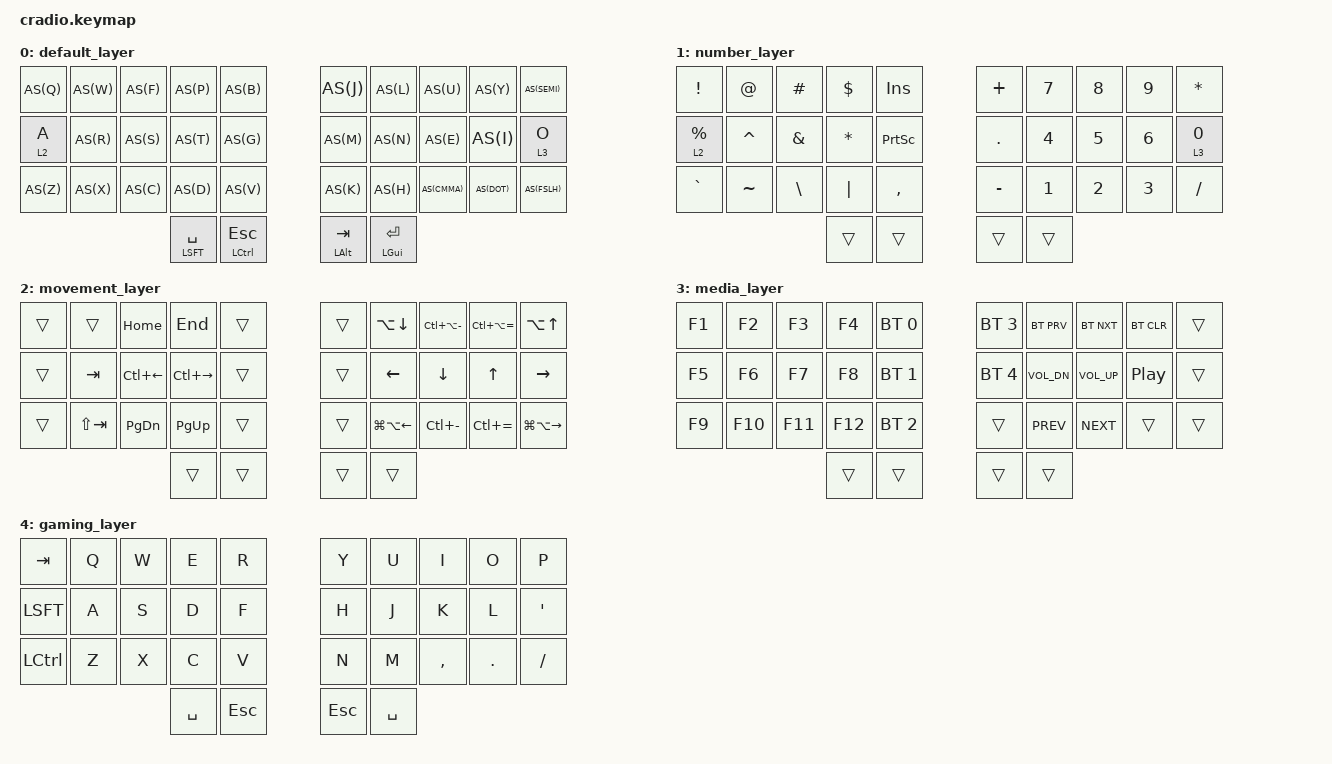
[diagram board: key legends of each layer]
/*
 * Copyright (c) 2020 The ZMK Contributors
 *
 * SPDX-License-Identifier: MIT
 */

#include <behaviors.dtsi>
#include <dt-bindings/zmk/keys.h>
#include <dt-bindings/zmk/bt.h>

#define DEFAULT 0
#define NUMBER 1
#define MOVEMENT 2
#define MEDIA 3
#define GAMING 4


/* Ex command to convert kp to autoshifted key
 *
 * :'<,'>s/\(\&kp \)\([A-Z]+\)/AS(\2)/g
 * */

&mt {
  //  flavor = "tap-preferred";
   // tapping_term_ms = <200>;
};

//give myself a bunch of time to stack modifiers
&sk {
     release-after-ms = <2000>;
};

//allow for adding modifiers to keys on sticky num layer
&sl {
    /delete-property/ quick-release;
};

&caps_word {
continue-list = <UNDERSCORE BSPC MINUS>;
};

#define AS(keycode) &as LS(keycode) keycode
/ {
    macros {
        summon_terminal: zed_em_kay {
            label = "ZM_summon_terminal";
            compatible = "zmk,behavior-macro";
            #binding-cells = <0>;
            bindings
                = <&macro_press &kp LGUI>
                , <&macro_tap &kp RET>
                , <&macro_release &kp LGUI>
                ;
        };

        ZMK_MACRO(my_macro,
            wait-ms = <30>;
            tap-ms = <40>;
            bindings = <&kp Z &kp M &kp K>;
        )
    };
};

/ {
    behaviors {
        as: auto_shift {
            compatible = "zmk,behavior-hold-tap";
            label = "AUTO_SHIFT";
            #binding-cells = <2>;
            tapping_term_ms = <145>;
            quick_tap_ms = <0>;
            flavor = "tap-preferred";
            bindings = <&kp>, <&kp>;
        };

        mo_tog: behavior_mo_tog {
            compatible = "zmk,behavior-hold-tap";
            label = "mo_tog";
            #binding-cells = <2>;
            flavor = "hold-preferred";
            tapping-term-ms = <200>;
            bindings = <&mo>, <&tog>;
        };

        /* sm: behavior_sticky_mo { */
        /*     compatible = "zmk,behavior-hold-tap"; */
        /*     label = "sticky_momentary"; */
        /*     #binding-cells = <2>; */
        /*     flavor = "hold-preferred"; */
        /*     tapping-term-ms = <200>; */
        /*     bindings = <&mo>, <&sl>; */
        /* }; */

        smt: behavior_sticky_mod_tap {
            compatible = "zmk,behavior-hold-tap";
            label = "sticky_mod_tap";
            #binding-cells = <2>;
            flavor = "hold-preferred";
            tapping-term-ms = <200>;
            bindings = <&sk>, <&kp>;
        };

        tph: tap-preferred-hold {
            compatible = "zmk,behavior-hold-tap";
            label = "sticky_mod_tap";
            #binding-cells = <2>;
            flavor = "tap-preferred";
            tapping-term-ms = <200>;
            bindings = <&kp>, <&kp>;
        };

    };

    combos {
        compatible = "zmk,combos";

        combo_del {
            timeout-ms = <50>;
            key-positions = <1 2>;
            bindings = <&kp DEL>;
        };

         combo_backspace {
            timeout-ms = <30>;
            key-positions = <11 12>;
            bindings = <&kp BSPC>;
        };

         combo_backslash {
            timeout-ms = <50>;
            key-positions = <7 8>;
            bindings = <AS(BACKSLASH)>;
        };

         combo_hyphen {
            timeout-ms = <50>;
            key-positions = <13 14>;
            bindings = <AS(MINUS)>;
        };

         combo_underscore {
            timeout-ms = <50>;
            key-positions = <23 24>;
            bindings = <&kp UNDERSCORE>;
        };

         combo_equals {
            timeout-ms = <50>;
            key-positions = <15 16>;
            bindings = <AS(EQUAL)>;
        };

         combo_plus {
            timeout-ms = <50>;
            key-positions = <25 26>;
            bindings = <&kp PLUS>;
        };

          combo_quote_mod {
            timeout-ms = <50>;
            key-positions = <17 18>;
            bindings = <&mt LGUI SQT>;
        };

          combo_double_quote {
            timeout-ms = <50>;
            key-positions = <27 28>;
            bindings = <&kp DOUBLE_QUOTES>;
        };

          combo_numlayer {
            timeout-ms = <50>;
            key-positions = <30 33>;
            bindings = <&sl 1>;
        };

          combo_reset {
            timeout-ms = <50>;
            key-positions = <1 2 7 8>;
            bindings = <&sys_reset>;
        };

          combo_bootloader {
            timeout-ms = <50>;
            key-positions = <3 4 5 6>;
            bindings = <&bootloader>;
        };

          combo_caps_word {
            timeout-ms = <50>;
            key-positions = <31 32>;
            bindings = <&caps_word>;
        };

          combo_num_layer_toggle {
            timeout-ms = <15>;
            key-positions = <10 13>;
            bindings = <&mo_tog 1 1>;
        };


        opening_brace {
            timeout-ms = <15>;
            key-positions = <2 3>;
            bindings = <&kp LBRC>;
        };

        closing_brace {
            timeout-ms = <15>;
            key-positions = <6 7>;
            bindings = <&kp RBRC>;
        };

        opening_par {
            timeout-ms = <15>;
            key-positions = <12 13>;
            bindings = <&kp LPAR>;
        };

        closing_par {
            timeout-ms = <15>;
            key-positions = <16 17>;
            bindings = <&kp RPAR>;
        };

        opening_bracket {
            timeout-ms = <15>;
            key-positions = <22 23>;
            bindings = <&kp LBKT>;
        };

        closing_bracket {
            timeout-ms = <15>;
            key-positions = <26 27>;
            bindings = <&kp RBKT>;
        };

        ralt_left {
            timeout-ms = <30>;
            key-positions = <21 22 23>;
            bindings = <&kp RALT>;
        };

        ralt_right {
            timeout-ms = <30>;
            key-positions = <26 27 28>;
            bindings = <&kp RALT>;
        };

        alt_tab {
            timeout-ms = <50>;
            key-positions = <30 31>;
            bindings = <&kp LA(TAB)>;
        };

        mod_tab {
            timeout-ms = <50>;
            key-positions = <32 33>;
            bindings = <&kp LG(TAB)>;
        };

        gaming_time {
            timeout-ms = <50>;
            key-positions = <2 11 13>;
            bindings = <&tog GAMING>;
        };

        all_thumbs {
            timeout-ms = <50>;
            key-positions = <30 31 32 33>;
            bindings = <&kp LG(LC(RET))>;
        };

        summon_terminal {
            timeout-ms = <50>;
            key-positions = <16 17 18>;
            bindings = <&kp LG(LA(T))>;
        };

        zmk_tester {
            timeout-ms = <50>;
            key-positions = <1 2 3>;
            bindings = <&my_macro>;
        };

};

keymap {
compatible = "zmk,keymap";
/*
                                                 reset
                           ┌─────┬─────────────────┴─────────────────┬─────┐
                           │     │                                   │     │
                           │     │            bootloader             │     │
                           │     │     ┌─────┬─────┴─────┬─────┐     │     │
                  |  q  |  w  |  f  |  p  |  b  |     |  j  |  l  |  u  |  y  |  ;  |
                  |    DEL    |     |     |     |     |     |     |     |     \     |

                  |  a  |  r  |  s  |  t  |  g  |     |  m  |  n  |  e  |  i  |  o  |
                  | lt2 |     |     |     |     |     |     |     |     |     | lt3 |
                  |     |     |     |     |     |     |     |     |     |     '     |
                  |    BSP    |     |     -     |     |     =     |     |    MOD    |

                  |  z  |  x  |  c  |  d  |  v  |     |  k  |  h  |  ,  |  .  |  /  |
                  |     |     |    sl1    |     |     |     |     |     |     |     |
                  |     |     |     |     _     |     |     +     |     |     |     |

                                    | SPC | ESC |     | TAB | ENT |
                                    | SFT | CTL |     | ALT | MOD |
                                       │     └─────┬─────┘     │
                                       │       caps_word       │
                                       │                       │
                                       └───────────┬───────────┘
                                                 ltog1
*/

                default_layer {
        bindings = <
        AS(Q) AS(W) AS(F) AS(P) AS(B)                       AS(J) AS(L)  AS(U)    AS(Y)   AS(SEMI)
        &lt 2 A AS(R) AS(S) AS(T) AS(G)                                 AS(M) AS(N) AS(E) AS(I) &lt 3 O
        AS(Z) AS(X) AS(C) AS(D) AS(V)                      AS(K) AS(H)  AS(CMMA) AS(DOT)  AS(FSLH)
                        &tph LSFT SPC &mt LCTL ESC                   &mt LALT TAB &mt LGUI RET
        >;
        };

/*
                this has changed! no longer a reference
                |  !  |  @  |  {  |  }  |  &  |     | INS |  7  |  8  |  9  |  *  |
                |    DEL    |     |     |     |     |     |     |     |     \     |

                |  #  |  $  |  (  |  )  |  *  |     |  .  |  4  |  5  |  6  |  0  |
                | lt2 |     |     |     |     |     |     |     |     |     | lt3 |
                |    BSP    |     |     -     |     |     =     |     |    MOD    |

                |  %  |  ^  |  [  |  ]  |  `  |     |SYSRQ|  1  |  2  |  3  |  /  |
                |     |     |     |     _     |     |     +     |     |     |     |

                                  | ( ) | ( ) |     | ( ) | ( ) |
*/

                number_layer {
        bindings = <
        &kp EXCL &kp AT &kp HASH &kp DLLR &kp INS                          &kp PLUS &kp N7  &kp N8    &kp N9   &kp ASTRK
        &lt 2 PRCNT &kp CARET &kp AMPS &kp ASTRK &kp PSCRN                   &kp DOT &kp N4 &kp N5 &kp N6 &lt 3 N0
        &kp GRAVE &kp TILDE &kp BSLH &kp PIPE &kp CMMA                      &kp MINUS &kp N1  &kp N2 &kp N3 &kp SLASH
                        &trans &trans               &trans &trans
        >;
        };

/*
                | ( ) | ( ) | HOM | END | ( ) |     | ( ) | A-↓ |Docs-|Docs+| A-↑ |

                | ( ) | TAB | C-← | C-→ | ( ) |     | ( ) |  ←  |  ↓  |  ↑  |  →  |

                | ( ) |S-TAB| PGD | PGU | ( ) |     | ( ) | A-← |Zoom-|Zoom+| A-→ |

                                  | ( ) | ( ) |     | ( ) | ( ) |
*/

                movement_layer {
        bindings = <
            &trans &trans &kp HOME &kp END &trans                 &trans &kp LA(DOWN) &kp LC(LA(MINUS)) &kp LC(LA(EQUAL)) &kp LA(UP)
    &trans &kp TAB &kp LC(LEFT) &kp LC(RIGHT) &trans      &trans &kp LEFT &kp DOWN &kp UP &kp RIGHT
    &trans &kp LS(TAB) &kp PG_DN &kp PG_UP &trans      &trans &kp LG(LA(LEFT)) &kp LC(MINUS) &kp LC(EQUAL) &kp LG(LA(RIGHT))
                         &trans &trans      &trans &trans
        >;
        };

/*
                | Fn1 | Fn2 | Fn3 | Fn4 |     |        |     |BT-P | BT-N | BT-C|    |

                | Fn5 | Fn6 | Fn7 | Fn8 |     |        |     | Vol-| Vol+|  ⏯  | ( ) |

                | Fn9 | F10 | F11 | F12 |     |        |     |  ⏮ |  ⏭  |     |     |

                                  |     |     |        |     |     |
*/

                media_layer {
        bindings = <
    &kp F1 &kp F2 &kp F3 &kp F4    &bt BT_SEL 0         &bt BT_SEL 3 &bt BT_PRV &bt BT_NXT &bt BT_CLR &trans
    &kp F5 &kp F6 &kp F7 &kp F8    &bt BT_SEL 1         &bt BT_SEL 4 &kp C_VOL_DN &kp C_VOL_UP &kp C_PP &trans
    &kp F9 &kp F10 &kp F11 &kp F12 &bt BT_SEL 2      &trans &kp C_PREV &kp C_NEXT &trans &trans
                         &trans &trans         &trans &trans
        >;
        };

/*
                |     |     |     |     |     |        |     |     |     |     |     |

                |     |     |     |     |     |        |     |     |     |     |     |

                |     |     |     |     |     |        |     |     |     |     |     |

                                  |     |     |        |     |     |
*/


                //right half can  be figured out later
                gaming_layer {
        bindings = <
            &kp TAB      &kp Q      &kp W      &kp E      &kp R          &kp Y      &kp U      &kp I      &kp O      &kp P

            &kp LSFT     &kp A      &kp S      &kp D      &kp F          &kp H      &kp J      &kp K      &kp L      &kp SQT

            &kp LCTL      &kp Z      &kp X      &kp C      &kp V          &kp N      &kp M      &kp COMMA  &kp DOT    &kp FSLH

                                             &kp SPC  &kp ESC          &kp ESC    &kp SPACE
        >;
        };

    };
};

// empty layers for easy creation later

/*
                |     |     |     |     |     |        |     |     |     |     |     |

                |     |     |     |     |     |        |     |     |     |     |     |

                |     |     |     |     |     |        |     |     |     |     |     |

                                  |     |     |        |     |     |
*/

/*
                empty_layer {
        bindings = <
    &trans &trans &trans &trans &trans      &trans &trans &trans &trans &trans
    &trans &trans &trans &trans &trans      &trans &trans &trans &trans &trans
    &trans &trans &trans &trans &trans      &trans &trans &trans &trans &trans
                         &trans &trans      &trans &trans
        >;
        };
*/
